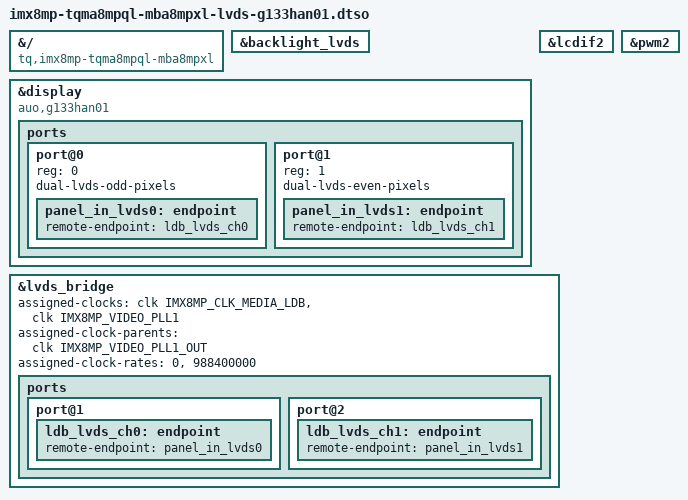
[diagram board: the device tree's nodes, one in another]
// SPDX-License-Identifier: (GPL-2.0-or-later OR MIT)
/*
 * Copyright (c) 2023 TQ-Systems GmbH <linux@ew.tq-group.com>,
 * D-82229 Seefeld, Germany.
 * Author: Alexander Stein
 */

/dts-v1/;
/plugin/;

#include <dt-bindings/clock/imx8mp-clock.h>

&{/} {
	compatible = "tq,imx8mp-tqma8mpql-mba8mpxl", "tq,imx8mp-tqma8mpql", "fsl,imx8mp";
};

&backlight_lvds {
	status = "okay";
};

&display {
	compatible = "auo,g133han01";
	status = "okay";

	ports {
		#address-cells = <1>;
		#size-cells = <0>;

		port@0 {
			reg = <0>;
			dual-lvds-odd-pixels;

			panel_in_lvds0: endpoint {
				remote-endpoint = <&ldb_lvds_ch0>;
			};
		};

		port@1 {
			reg = <1>;
			dual-lvds-even-pixels;

			panel_in_lvds1: endpoint {
				remote-endpoint = <&ldb_lvds_ch1>;
			};
		};
	};
};

&lcdif2 {
	status = "okay";
};

&lvds_bridge {
	assigned-clocks = <&clk IMX8MP_CLK_MEDIA_LDB>,
				 <&clk IMX8MP_VIDEO_PLL1>;
	assigned-clock-parents = <&clk IMX8MP_VIDEO_PLL1_OUT>;
	assigned-clock-rates = <0>, <988400000>;
	status = "okay";

	ports {
		port@1 {
			ldb_lvds_ch0: endpoint {
				remote-endpoint = <&panel_in_lvds0>;
			};
		};

		port@2 {
			ldb_lvds_ch1: endpoint {
				remote-endpoint = <&panel_in_lvds1>;
			};
		};
	};
};

&pwm2 {
	status = "okay";
};
